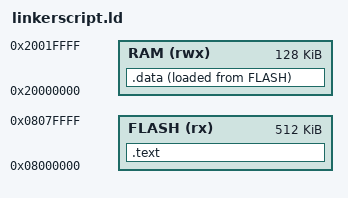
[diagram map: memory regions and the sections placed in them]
ENTRY(Reset_Handler)

MEMORY
{
  FLASH (rx)  : ORIGIN = 0x08000000, LENGTH = 512K
  RAM   (rwx) : ORIGIN = 0x20000000, LENGTH = 128K
}

_estack = ORIGIN(RAM) + LENGTH(RAM) /* Initial Value of stack pointer -> 0x20020000 */


SECTIONS {
  .text :
  {
    KEEP(*(.isr_vector))
    *(.text*)
    *(.rodata*)
    _etext = .;
  } > FLASH

  .data :
  {
    . = ALIGN(4)
    _sdata = .;
    *(.data*)
    _edata = .;
  } > RAM AT > FLASH 

  .bss
  {
    _sbss = .;
    *(.bss*)
    *(COMMON)
    _ebss = .;
  } > RAM
}
